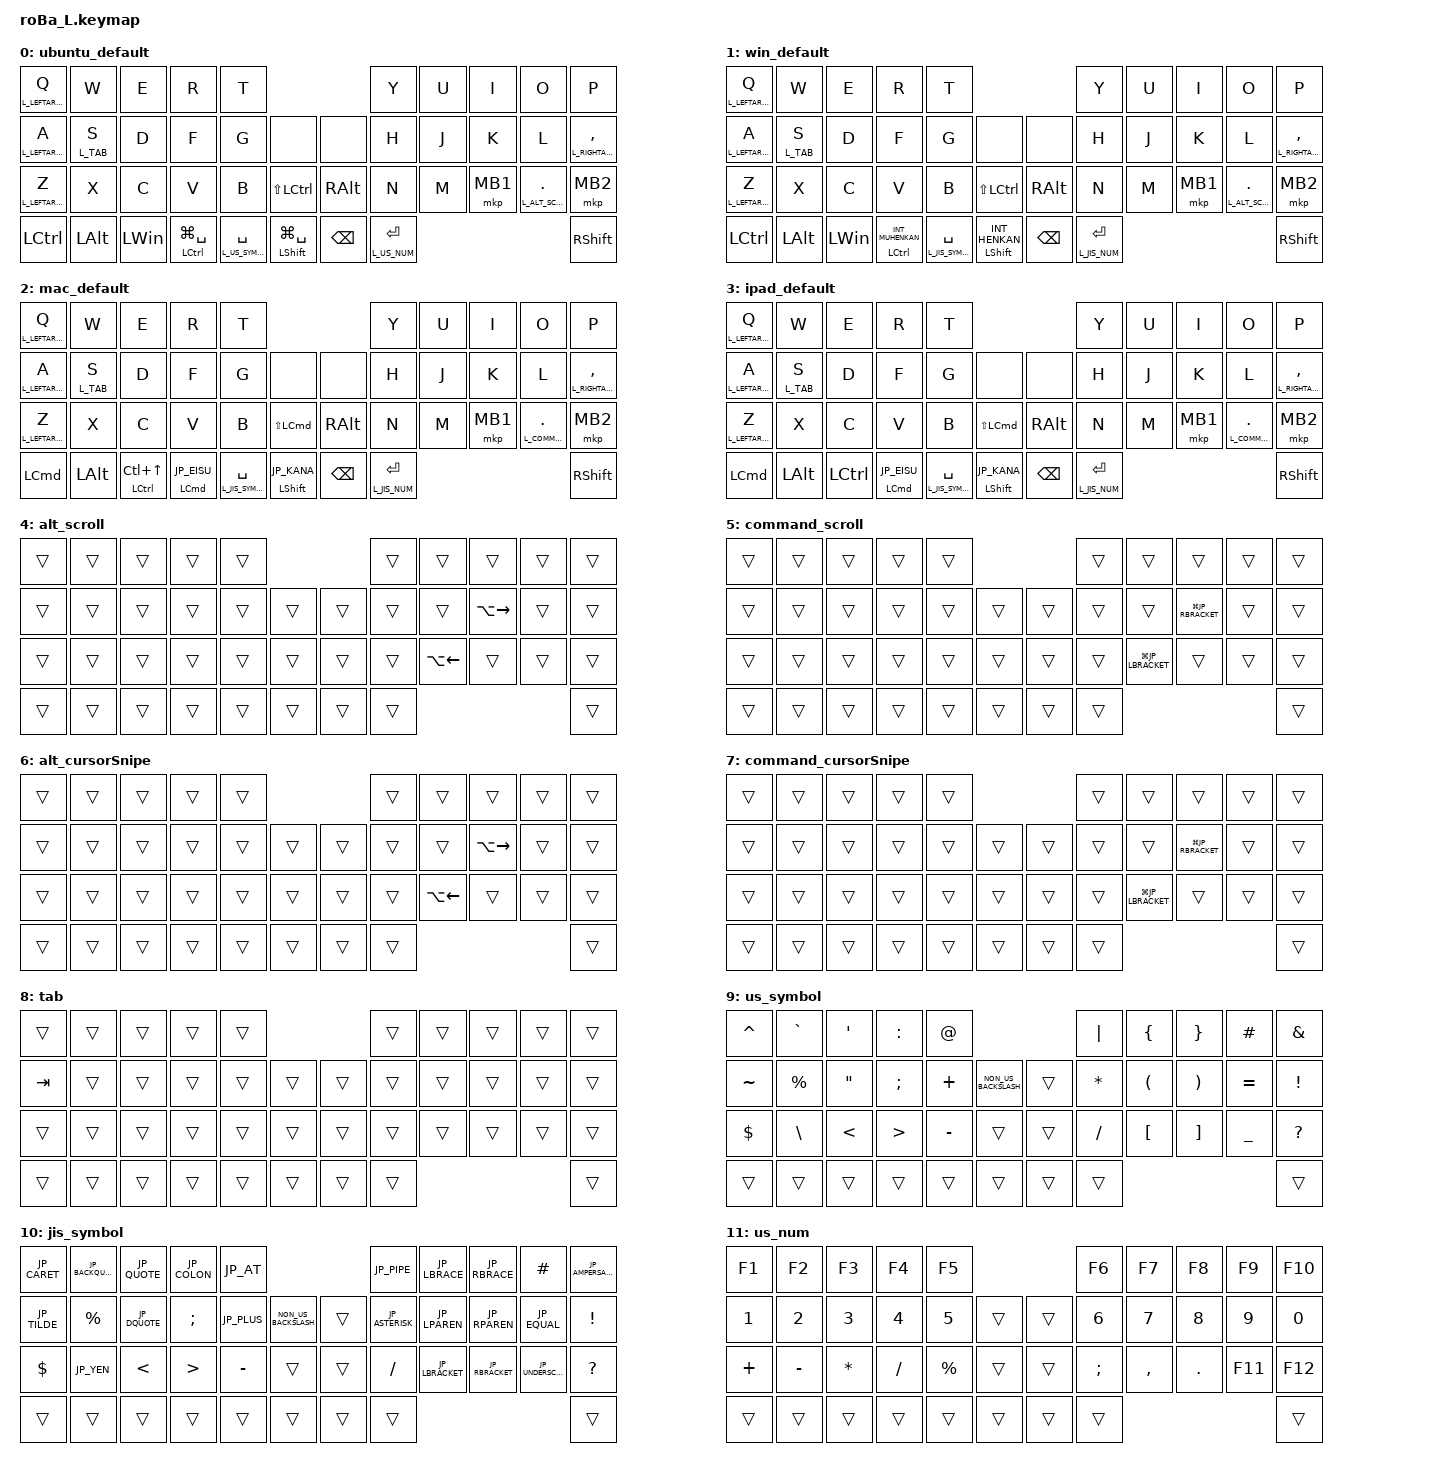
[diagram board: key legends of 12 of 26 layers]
// OS設定を日本語キーボードのまま使用するための変換定義
#define JP_DQUOTE       AT                // "
#define JP_AMPERSAND    CARET             // &
#define JP_QUOTE        AMPERSAND         // '
#define JP_EQUAL        UNDER             // =
#define JP_CARET        EQUAL             // ^
#define JP_YEN          0x89              // ¥
#define JP_PLUS         COLON             // +
#define JP_TILDE        PLUS              // ~
#define JP_PIPE         LS(0x89)          // |
#define JP_AT           LEFT_BRACKET      // @
#define JP_COLON        SINGLE_QUOTE      // :
#define JP_ASTERISK     DOUBLE_QUOTES     // *
#define JP_BACKQUOTE    LEFT_BRACE        // `
#define JP_UNDERSCORE   LS(0x87)          // _
#define JP_LBRACKET     RIGHT_BRACKET     // [
#define JP_RBRACKET     BACKSLASH         // ]
#define JP_LPAREN       ASTERISK          // (
#define JP_RPAREN       LEFT_PARENTHESIS  // )
#define JP_LBRACE       RIGHT_BRACE       // {
#define JP_RBRACE       PIPE              // }
#define JP_KANA         LANGUAGE_1        // かな
#define JP_EISU         LANGUAGE_2        // 英数
#define JP_HANZEN       GRAVE             // 半角/全角

#include <behaviors.dtsi>
#include <dt-bindings/zmk/bt.h>
#include <dt-bindings/zmk/keys.h>
#include <dt-bindings/zmk/pointing.h>


// Layer名を定義
#define L_UBUNTU_DEFAULT                 0
#define L_WIN_DEFAULT                    1
#define L_MAC_DEFAULT                    2
#define L_IPAD_DEFAULT                   3
#define L_ALT_SCROLL                     4
#define L_COMMAND_SCROLL                 5
#define L_ALT_CURSORSNIPE                6
#define L_COMMAND_CURSORSNIPE            7
#define L_TAB                            8
#define L_US_SYMBOL                      9
#define L_JIS_SYMBOL                    10
#define L_US_NUM                        11
#define L_JIS_NUM                       12
#define L_UBUNTU_NUMPAD                 13
#define L_WIN_NUMPAD                    14
#define L_MAC_IPAD_NUMPAD               15
#define L_UBUNTU_FUNCTION               16
#define L_WIN_FUNCTION                  17
#define L_MAC_FUNCTION                  18
#define L_IPAD_FUNCTION                 19
#define L_LEFTARROW                     20
#define L_LEFTARROW_ENABLETRACKBALL     21
#define L_RIGHTARROW                    22
#define L_RIGHTARROW_ENABLETRACKBALL    23
#define L_VOLUME                        24
#define L_BLUETOOTH                     25


&mt {
    flavor = "balanced";
    quick-tap-ms = <0>;
};

/ {
    combos {
        compatible = "zmk,combos";

        middleCkick {
            bindings = <&mkp MCLK>;
            key-positions = <33 31>;
        };

        bluetoothLayer {
            bindings = <&mo L_BLUETOOTH>;
            key-positions = <41 40>;
        };

        tab {
            bindings = <&kp TAB>;
            key-positions = <10 11>;
        };

        ubuntu_esc1_funcitonLayer {
            bindings = <&lt L_UBUNTU_FUNCTION ESCAPE>;
            key-positions = <41 38>;
            layers = <L_UBUNTU_DEFAULT>;
        };

        win_esc1_funcitonLayer {
            bindings = <&lt L_WIN_FUNCTION ESCAPE>;
            key-positions = <41 38>;
            layers = <L_WIN_DEFAULT>;
        };

        mac_esc1_funcitonLayer {
            bindings = <&lt L_MAC_FUNCTION ESCAPE>;
            key-positions = <41 38>;
            layers = <L_MAC_DEFAULT>;
        };

        ipad_esc1_funcitonLayer {
            bindings = <&lt L_IPAD_FUNCTION ESCAPE>;
            key-positions = <41 38>;
            layers = <L_IPAD_DEFAULT>;
        };

        esc2 {
            bindings = <&kp ESCAPE>;
            key-positions = <0 1>;
        };

        ubuntu_numPadLayer {
            bindings = <&mo L_UBUNTU_NUMPAD>;
            key-positions = <28 41>;
            layers = <L_UBUNTU_DEFAULT>;
        };

        win_numPadLayer {
            bindings = <&mo L_WIN_NUMPAD>;
            key-positions = <28 41>;
            layers = <L_WIN_DEFAULT>;
        };

        mac_ipad_numPadLayer {
            bindings = <&mo L_MAC_IPAD_NUMPAD>;
            key-positions = <28 41>;
            layers = <L_MAC_DEFAULT L_IPAD_DEFAULT>;
        };

        volume {
            bindings = <&mo L_VOLUME>;
            key-positions = <37 38>;
            layers = <L_UBUNTU_DEFAULT L_WIN_DEFAULT L_MAC_DEFAULT L_IPAD_DEFAULT>;
        };

    };

    macros {
        to_layer_0: to_layer_0 {
            compatible = "zmk,behavior-macro-one-param";
            #binding-cells = <1>;
            bindings = <&to 1 &macro_param_1to1 &kp MACRO_PLACEHOLDER>;
            label = "TO_LAYER_0";
        };

        BT_ubuntu: BT_ubuntu {
            compatible = "zmk,behavior-macro";
            #binding-cells = <0>;
            bindings =
            <&bt BT_SEL 0>,
            <&to L_UBUNTU_DEFAULT>;

            label = "BT_ubuntu";
        };

        BT_win: BT_win {
            compatible = "zmk,behavior-macro";
            #binding-cells = <0>;
            bindings =
            <&bt BT_SEL 1>,
            <&to L_WIN_DEFAULT>;

            label = "BT_win";
        };

        BT_mac: BT_mac {
            compatible = "zmk,behavior-macro";
            #binding-cells = <0>;
            bindings =
            <&bt BT_SEL 2>,
            <&to L_MAC_DEFAULT>;

            label = "BT_mac";
        };

        BT_ipad: BT_ipad {
            compatible = "zmk,behavior-macro";
            #binding-cells = <0>;
            bindings =
            <&bt BT_SEL 3>,
            <&to L_IPAD_DEFAULT>;

            label = "BT_ipad";
        };
    };

    behaviors {
        lt_to_layer_0: lt_to_layer_0 {
            compatible = "zmk,behavior-hold-tap";
            label = "LAYER_TAP_TO_0";
            bindings = <&mo>, <&to_layer_0>;

            #binding-cells = <2>;
            tapping-term-ms = <200>;
        };
    };

    keymap {
        compatible = "zmk,keymap";

        ubuntu_default {
            bindings = <
&lt L_LEFTARROW_ENABLETRACKBALL Q   &kp W         &kp E         &kp R                   &kp T                                                                &kp Y               &kp U  &kp I     &kp O                     &kp P
&lt L_LEFTARROW A                   &lt L_TAB S   &kp D         &kp F                   &kp G                  &none                          &none          &kp H               &kp J  &kp K     &kp L                     &lt L_RIGHTARROW COMMA
&lt L_LEFTARROW Z                   &kp X         &kp C         &kp V                   &kp B                  &kp LS(LCTRL)                  &kp RALT       &kp N               &kp M  &mkp MB1  &lt L_ALT_SCROLL PERIOD   &mkp MB2
&kp LCTRL                           &kp LEFT_ALT  &kp LEFT_WIN  &mt LCTRL LG(SPACE)     &lt L_US_SYMBOL SPACE  &mt LEFT_SHIFT LG(SPACE)       &kp BACKSPACE  &lt L_US_NUM ENTER                                             &kp RIGHT_SHIFT
            >;
        };

        win_default {
            bindings = <
&lt L_LEFTARROW_ENABLETRACKBALL Q   &kp W         &kp E         &kp R                   &kp T                                                                 &kp Y                &kp U  &kp I     &kp O                     &kp P
&lt L_LEFTARROW A                   &lt L_TAB S   &kp D         &kp F                   &kp G                   &none                          &none          &kp H                &kp J  &kp K     &kp L                     &lt L_RIGHTARROW COMMA
&lt L_LEFTARROW Z                   &kp X         &kp C         &kp V                   &kp B                   &kp LS(LCTRL)                  &kp RALT       &kp N                &kp M  &mkp MB1  &lt L_ALT_SCROLL PERIOD   &mkp MB2
&kp LCTRL                           &kp LEFT_ALT  &kp LEFT_WIN  &mt LCTRL INT_MUHENKAN  &lt L_JIS_SYMBOL SPACE  &mt LEFT_SHIFT INT_HENKAN      &kp BACKSPACE  &lt L_JIS_NUM ENTER                                             &kp RIGHT_SHIFT
            >;
        };

        mac_default {
            bindings = <
&lt L_LEFTARROW_ENABLETRACKBALL Q   &kp W         &kp E                   &kp R                     &kp T                                                          &kp Y                &kp U  &kp I     &kp O                        &kp P
&lt L_LEFTARROW A                   &lt L_TAB S   &kp D                   &kp F                     &kp G                   &none                   &none          &kp H                &kp J  &kp K     &kp L                        &lt L_RIGHTARROW COMMA
&lt L_LEFTARROW Z                   &kp X         &kp C                   &kp V                     &kp B                   &kp LS(LEFT_COMMAND)    &kp RALT       &kp N                &kp M  &mkp MB1  &lt L_COMMAND_SCROLL PERIOD  &mkp MB2
&kp LEFT_COMMAND                    &kp LEFT_ALT  &mt LCTRL LC(UP_ARROW)  &mt LEFT_COMMAND JP_EISU  &lt L_JIS_SYMBOL SPACE  &mt LEFT_SHIFT JP_KANA  &kp BACKSPACE  &lt L_JIS_NUM ENTER                                                &kp RIGHT_SHIFT
            >;
        };

        ipad_default {
            bindings = <
&lt L_LEFTARROW_ENABLETRACKBALL Q   &kp W         &kp E         &kp R                     &kp T                                                          &kp Y               &kp U  &kp I     &kp O                        &kp P
&lt L_LEFTARROW A                   &lt L_TAB S   &kp D         &kp F                     &kp G                   &none                   &none          &kp H               &kp J  &kp K     &kp L                        &lt L_RIGHTARROW COMMA
&lt L_LEFTARROW Z                   &kp X         &kp C         &kp V                     &kp B                   &kp LS(LEFT_COMMAND)    &kp RALT       &kp N               &kp M  &mkp MB1  &lt L_COMMAND_SCROLL PERIOD  &mkp MB2
&kp LEFT_COMMAND                    &kp LEFT_ALT  &kp LCTRL     &mt LEFT_COMMAND JP_EISU  &lt L_JIS_SYMBOL SPACE  &mt LEFT_SHIFT JP_KANA  &kp BACKSPACE  &lt L_JIS_NUM ENTER                                               &kp RIGHT_SHIFT
            >;
        };

        alt_scroll {
            bindings = <
&trans  &trans  &trans  &trans  &trans                      &trans  &trans              &trans               &trans  &trans
&trans  &trans  &trans  &trans  &trans  &trans      &trans  &trans  &trans              &kp LA(RIGHT_ARROW)  &trans  &trans
&trans  &trans  &trans  &trans  &trans  &trans      &trans  &trans  &kp LA(LEFT_ARROW)  &trans               &trans  &trans
&trans  &trans  &trans  &trans  &trans  &trans      &trans  &trans                                                   &trans
            >;
        };

        command_scroll {
            bindings = <
&trans  &trans  &trans  &trans  &trans                      &trans  &trans               &trans               &trans  &trans
&trans  &trans  &trans  &trans  &trans  &trans      &trans  &trans  &trans               &kp LG(JP_RBRACKET)  &trans  &trans
&trans  &trans  &trans  &trans  &trans  &trans      &trans  &trans  &kp LG(JP_LBRACKET)  &trans               &trans  &trans
&trans  &trans  &trans  &trans  &trans  &trans      &trans  &trans                                                    &trans
            >;
        };

        alt_cursorSnipe {
            bindings = <
&trans  &trans  &trans  &trans  &trans                      &trans  &trans              &trans               &trans  &trans
&trans  &trans  &trans  &trans  &trans  &trans      &trans  &trans  &trans              &kp LA(RIGHT_ARROW)  &trans  &trans
&trans  &trans  &trans  &trans  &trans  &trans      &trans  &trans  &kp LA(LEFT_ARROW)  &trans               &trans  &trans
&trans  &trans  &trans  &trans  &trans  &trans      &trans  &trans                                                   &trans
            >;
        };

        command_cursorSnipe {
            bindings = <
&trans  &trans  &trans  &trans  &trans                      &trans  &trans               &trans               &trans  &trans
&trans  &trans  &trans  &trans  &trans  &trans      &trans  &trans  &trans               &kp LG(JP_RBRACKET)  &trans  &trans
&trans  &trans  &trans  &trans  &trans  &trans      &trans  &trans  &kp LG(JP_LBRACKET)  &trans               &trans  &trans
&trans  &trans  &trans  &trans  &trans  &trans      &trans  &trans                                                    &trans
            >;
        };

        tab {
            bindings = <
&trans   &trans  &trans  &trans  &trans                      &trans  &trans  &trans  &trans  &trans
&kp TAB  &trans  &trans  &trans  &trans  &trans      &trans  &trans  &trans  &trans  &trans  &trans
&trans   &trans  &trans  &trans  &trans  &trans      &trans  &trans  &trans  &trans  &trans  &trans
&trans   &trans  &trans  &trans  &trans  &trans      &trans  &trans                          &trans
            >;
        };

        us_symbol {
            bindings = <
&kp CARET   &kp GRAVE      &kp SINGLE_QUOTE   &kp COLON         &kp AT_SIGN                                    &kp PIPE      &kp LEFT_BRACE        &kp RIGHT_BRACE        &kp HASH        &kp AMPERSAND
&kp TILDE   &kp PERCENT    &kp DOUBLE_QUOTES  &kp SEMICOLON     &kp PLUS     &kp NON_US_BACKSLASH      &trans  &kp ASTERISK  &kp LEFT_PARENTHESIS  &kp RIGHT_PARENTHESIS  &kp EQUAL       &kp EXCLAMATION
&kp DOLLAR  &kp BACKSLASH  &kp LESS_THAN      &kp GREATER_THAN  &kp MINUS    &trans                    &trans  &kp SLASH     &kp LEFT_BRACKET      &kp RIGHT_BRACKET      &kp UNDERSCORE  &kp QUESTION
&trans      &trans         &trans             &trans            &trans       &trans                    &trans  &trans                                                                     &trans
            >;
        };

        jis_symbol {
            bindings = <
&kp JP_CARET  &kp JP_BACKQUOTE  &kp JP_QUOTE   &kp JP_COLON      &kp JP_AT                                     &kp JP_PIPE      &kp JP_LBRACE    &kp JP_RBRACE    &kp HASH           &kp JP_AMPERSAND
&kp JP_TILDE  &kp PERCENT       &kp JP_DQUOTE  &kp SEMICOLON     &kp JP_PLUS   &kp NON_US_BACKSLASH    &trans  &kp JP_ASTERISK  &kp JP_LPAREN    &kp JP_RPAREN    &kp JP_EQUAL       &kp EXCLAMATION
&kp DOLLAR    &kp JP_YEN        &kp LESS_THAN  &kp GREATER_THAN  &kp MINUS     &trans                  &trans  &kp SLASH        &kp JP_LBRACKET  &kp JP_RBRACKET  &kp JP_UNDERSCORE  &kp QUESTION
&trans        &trans            &trans         &trans             &trans       &trans                  &trans  &trans                                                                &trans
            >;
        };

        us_num {
            bindings = <
&kp F1        &kp F2        &kp F3        &kp F4        &kp F5                          &kp F6          &kp F7        &kp F8        &kp F9        &kp F10
&kp NUMBER_1  &kp NUMBER_2  &kp NUMBER_3  &kp NUMBER_4  &kp NUMBER_5  &trans    &trans  &kp NUMBER_6    &kp NUMBER_7  &kp NUMBER_8  &kp NUMBER_9  &kp NUMBER_0
&kp PLUS      &kp MINUS     &kp ASTERISK  &kp SLASH     &kp PERCENT   &trans    &trans  &kp SEMICOLON   &kp COMMA     &kp PERIOD    &kp F11       &kp F12
&trans        &trans        &trans        &trans        &trans        &trans    &trans  &trans                                                    &trans
            >;
        };

        jis_num {
            bindings = <
&kp F1        &kp F2        &kp F3            &kp F4        &kp F5                            &kp F6            &kp F7        &kp F8          &kp F9        &kp F10
&kp NUMBER_1  &kp NUMBER_2  &kp NUMBER_3      &kp NUMBER_4  &kp NUMBER_5    &trans    &trans  &kp NUMBER_6      &kp NUMBER_7  &kp NUMBER_8    &kp NUMBER_9  &kp NUMBER_0
&kp JP_PLUS   &kp MINUS     &kp JP_ASTERISK   &kp SLASH     &kp PERCENT     &trans    &trans  &kp SEMICOLON     &kp COMMA     &kp PERIOD      &kp F11       &kp F12
&trans        &trans        &trans            &trans        &trans          &trans    &trans  &trans                                                        &trans
            >;
        };

        ubuntu_numPad {
            bindings = <
&kp SLASH     &kp NUMBER_1  &kp NUMBER_2           &kp NUMBER_3  &kp MINUS                            &kp GRAVE    &kp SEMICOLON  &kp DOUBLE_QUOTES  &kp COLON     &kp SINGLE_QUOTE
&kp ASTERISK  &kp NUMBER_4  &kp NUMBER_5           &kp NUMBER_6  &kp PLUS    &kp PERCENT      &trans  &kp PERIOD   &kp PLUS       &kp MINUS          &kp ASTERISK  &kp SLASH
&kp NUMBER_0  &kp NUMBER_7  &kp NUMBER_8           &kp NUMBER_9  &kp PERIOD  &kp EQUAL        &trans  &kp PERCENT  &kp PIPE       &kp AMPERSAND      &kp EQUAL     &kp COMMA
&trans        &trans        &mt LEFT_ALT NUMBER_0  &trans        &trans      &trans           &trans  &trans                                                       &trans
            >;
        };

        win_numPad {
            bindings = <
&kp SLASH     &kp NUMBER_1  &kp NUMBER_2           &kp NUMBER_3  &kp MINUS                          &kp JP_BACKQUOTE  &kp SEMICOLON  &kp JP_DQUOTE   &kp COLON     &kp JP_QUOTE
&kp ASTERISK  &kp NUMBER_4  &kp NUMBER_5           &kp NUMBER_6  &kp PLUS    &kp PERCENT    &trans  &kp PERIOD        &kp PLUS       &kp MINUS       &kp ASTERISK  &kp SLASH
&kp NUMBER_0  &kp NUMBER_7  &kp NUMBER_8           &kp NUMBER_9  &kp PERIOD  &kp EQUAL      &trans  &kp PERCENT       &kp PIPE       &kp AMPERSAND   &kp EQUAL     &kp COMMA
&trans        &trans        &mt LEFT_ALT NUMBER_0  &trans        &trans      &trans         &trans  &trans                                                         &trans
            >;
        };

        mac_ipad_numPad {
            bindings = <
&kp SLASH     &kp NUMBER_1  &kp NUMBER_2               &kp NUMBER_3  &kp MINUS                          &kp JP_BACKQUOTE  &kp SEMICOLON  &kp JP_DQUOTE   &kp COLON     &kp JP_QUOTE
&kp ASTERISK  &kp NUMBER_4  &kp NUMBER_5               &kp NUMBER_6  &kp PLUS    &kp PERCENT    &trans  &kp PERIOD        &kp PLUS       &kp MINUS       &kp ASTERISK  &kp SLASH
&kp NUMBER_0  &kp NUMBER_7  &kp NUMBER_8               &kp NUMBER_9  &kp PERIOD  &kp EQUAL      &trans  &kp PERCENT       &kp PIPE       &kp AMPERSAND   &kp EQUAL     &kp COMMA
&trans        &trans        &mt LEFT_COMMAND NUMBER_0  &trans        &trans      &trans         &trans  &trans                                                         &trans
            >;
        };

        ubuntu_function {
            bindings = <
&kp F10  &kp F1  &kp F2  &kp F3  &trans                       &kp C_VOLUME_UP    &kp LC(LG(LEFT_ARROW))  &kp LC(LG(RIGHT_ARROW))  &trans   &trans
&kp F11  &kp F4  &kp F5  &kp F6  &trans  &trans      &trans   &kp C_VOLUME_DOWN  &kp PRINTSCREEN         &trans                   &trans   &trans
&kp F12  &kp F7  &kp F8  &kp F9  &trans  &trans      &trans   &kp K_MUTE         &trans                  &trans                   &trans   &trans
&trans   &trans  &trans  &trans  &trans  &trans      &trans   &trans                                                                       &trans

            >;
        };

        win_function {
            bindings = <
&kp F10  &kp F1  &kp F2  &kp F3  &trans                       &kp C_VOLUME_UP    &kp LC(LG(LEFT_ARROW))  &kp LC(LG(RIGHT_ARROW))  &kp LC(LG(D))  &kp LC(LG(F4))
&kp F11  &kp F4  &kp F5  &kp F6  &trans  &trans      &trans   &kp C_VOLUME_DOWN  &kp PRINTSCREEN         &trans                   &kp LG(LC(T))  &kp LG(TAB)
&kp F12  &kp F7  &kp F8  &kp F9  &trans  &trans      &trans   &kp K_MUTE         &kp LC(LG(C))           &kp LC(F8)               &kp LC(LG(Z))  &trans
&trans   &trans  &trans  &trans  &trans  &trans      &trans   &trans                                                                             &trans
            >;
        };

        mac_function {
            bindings = <
&kp F10  &kp F1  &kp F2  &kp F3  &trans                    &kp C_VOLUME_UP    &kp LC(LEFT_ARROW)  &kp LC(RIGHT_ARROW)  &trans         &trans
&kp F11  &kp F4  &kp F5  &kp F6  &trans  &trans    &trans  &kp C_VOLUME_DOWN  &kp LG(LS(3))       &kp LG(LS(4))        &kp LG(LS(5))  &trans
&kp F12  &kp F7  &kp F8  &kp F9  &trans  &trans    &trans  &kp K_MUTE         &kp LG(LS(C))       &kp LG(LS(2))        &trans         &trans
&trans   &trans  &trans  &trans  &trans  &trans    &trans  &trans                                                                     &trans
            >;
        };

        ipad_function {
            bindings = <
&kp F10  &kp F1  &kp F2  &kp F3  &trans                    &kp C_VOLUME_UP    &trans  &trans  &trans  &trans
&kp F11  &kp F4  &kp F5  &kp F6  &trans  &trans    &trans  &kp C_VOLUME_DOWN  &trans  &trans  &trans  &trans
&kp F12  &kp F7  &kp F8  &kp F9  &trans  &trans    &trans  &kp K_MUTE         &trans  &trans  &trans  &trans
&trans   &trans  &trans  &trans  &trans  &trans    &trans  &trans                                     &trans
            >;
        };


        leftArrow {
            bindings = <
&trans  &kp HOME        &kp UP_ARROW    &kp END          &kp PAGE_UP                        &trans  &trans  &trans  &trans  &trans
&trans  &kp LEFT_ARROW  &kp DOWN_ARROW  &kp RIGHT_ARROW  &kp PAGE_DOWN  &trans      &trans  &trans  &trans  &trans  &trans  &trans
&trans  &kp BACKSPACE   &kp DELETE      &trans           &trans         &trans      &trans  &trans  &trans  &trans  &trans  &trans
&trans  &trans          &trans          &trans           &trans         &trans      &trans  &trans                          &trans
            >;
        };

        leftArrow_enableTrackball {
            bindings = <
&trans  &kp HOME        &kp UP_ARROW    &kp END          &kp PAGE_UP                        &trans  &trans  &trans  &trans  &trans
&trans  &kp LEFT_ARROW  &kp DOWN_ARROW  &kp RIGHT_ARROW  &kp PAGE_DOWN  &trans      &trans  &trans  &trans  &trans  &trans  &trans
&trans  &kp BACKSPACE   &kp DELETE      &trans           &trans         &trans      &trans  &trans  &trans  &trans  &trans  &trans
&trans  &trans          &trans          &trans           &trans         &trans      &trans  &trans                          &trans
            >;
        };

        rightArrow {
            bindings = <
&trans  &trans  &trans  &trans  &trans                      &kp PAGE_UP    &kp HOME  &kp UP         &kp END     &trans
&trans  &trans  &trans  &trans  &trans  &trans      &trans  &kp PAGE_DOWN  &kp LEFT  &kp DOWN       &kp RIGHT   &trans
&trans  &trans  &trans  &trans  &trans  &trans      &trans  &trans         &trans    &kp BACKSPACE  &kp DELETE  &trans
&trans  &trans  &trans  &trans  &trans  &trans      &trans  &trans                                              &trans
            >;
        };

        rightArrow_enableTrackball {
            bindings = <
&trans  &trans  &trans  &trans  &trans                      &kp PAGE_UP    &kp HOME  &kp UP         &kp END     &trans
&trans  &trans  &trans  &trans  &trans  &trans      &trans  &kp PAGE_DOWN  &kp LEFT  &kp DOWN       &kp RIGHT   &trans
&trans  &trans  &trans  &trans  &trans  &trans      &trans  &trans         &trans    &kp BACKSPACE  &kp DELETE  &trans
&trans  &trans  &trans  &trans  &trans  &trans      &trans  &trans                                              &trans
            >;
        };

        volume {
            bindings = <
&trans  &trans  &trans  &trans  &trans                      &trans  &trans  &trans  &trans  &trans
&trans  &trans  &trans  &trans  &trans  &trans      &trans  &trans  &trans  &trans  &trans  &trans
&trans  &trans  &trans  &trans  &trans  &trans      &trans  &trans  &trans  &trans  &trans  &trans
&trans  &trans  &trans  &trans  &trans  &trans      &trans  &trans                  &trans  &trans
            >;
        };

        bluetooth {
            bindings = <
&trans  &trans  &trans  &trans  &trans                           &BT_ubuntu            &BT_win            &BT_mac            &BT_ipad            &bt BT_SEL 4
&trans  &trans  &trans  &trans  &trans  &trans      &bootloader  &to L_UBUNTU_DEFAULT  &to L_WIN_DEFAULT  &to L_MAC_DEFAULT  &to L_IPAD_DEFAULT  &trans
&trans  &trans  &trans  &trans  &trans  &trans      &bootloader  &trans                &trans             &trans             &trans              &bt BT_CLR
&trans  &trans  &trans  &trans  &trans  &trans      &trans       &trans                                                                          &bt BT_CLR_ALL
            >;
        };
    };
};
